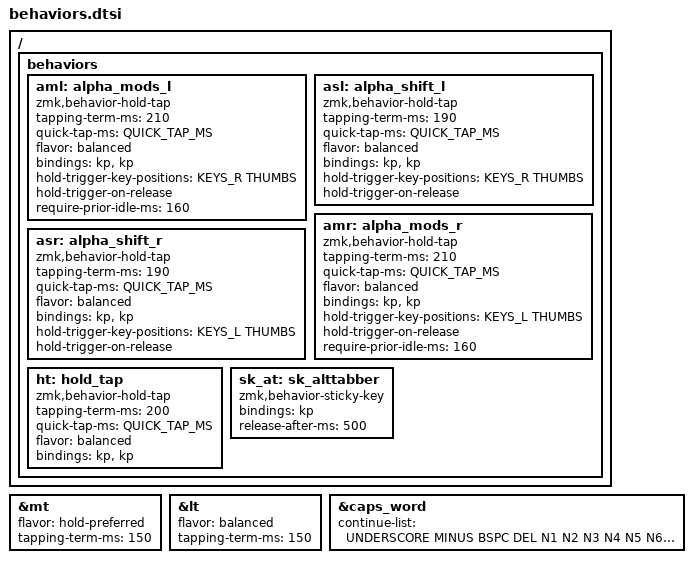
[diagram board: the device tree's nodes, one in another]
#include <behaviors.dtsi>

#define QUICK_TAP_MS 175

&mt {
    flavor = "hold-preferred";
    tapping-term-ms = <150>;
};

&lt {
    flavor = "balanced";
    tapping-term-ms = <150>;
};

&caps_word {
    continue-list = <UNDERSCORE MINUS BSPC DEL N1 N2 N3 N4 N5 N6 N7 N8 N9 N0>;
};

/ {
    behaviors {
        aml: alpha_mods_l {
            compatible = "zmk,behavior-hold-tap";
            #binding-cells = <2>;
            tapping-term-ms = <210>;
            quick-tap-ms = <QUICK_TAP_MS>;
            flavor = "balanced";
            bindings = <&kp>, <&kp>;
            hold-trigger-key-positions = <KEYS_R THUMBS>;
            hold-trigger-on-release;
            require-prior-idle-ms = <160>;
        };
        asl: alpha_shift_l {
            compatible = "zmk,behavior-hold-tap";
            #binding-cells = <2>;
            tapping-term-ms = <190>;
            quick-tap-ms = <QUICK_TAP_MS>;
            flavor = "balanced";
            bindings = <&kp>, <&kp>;
            hold-trigger-key-positions = <KEYS_R THUMBS>;
            hold-trigger-on-release;
        };
        amr: alpha_mods_r {
            compatible = "zmk,behavior-hold-tap";
            #binding-cells = <2>;
            tapping-term-ms = <210>;
            quick-tap-ms = <QUICK_TAP_MS>;
            flavor = "balanced";
            bindings = <&kp>, <&kp>;
            hold-trigger-key-positions = <KEYS_L THUMBS>;
            hold-trigger-on-release;
            require-prior-idle-ms = <160>;
        };
        asr: alpha_shift_r {
            compatible = "zmk,behavior-hold-tap";
            #binding-cells = <2>;
            tapping-term-ms = <190>;
            quick-tap-ms = <QUICK_TAP_MS>;
            flavor = "balanced";
            bindings = <&kp>, <&kp>;
            hold-trigger-key-positions = <KEYS_L THUMBS>;
            hold-trigger-on-release;
        };
        ht: hold_tap {
            compatible = "zmk,behavior-hold-tap";
            #binding-cells = <2>;
            tapping-term-ms = <200>;
            quick-tap-ms = <QUICK_TAP_MS>;
            flavor = "balanced";
            bindings = <&kp>, <&kp>;
        };
        // sticky key to be used for alt-tab macro
        sk_at: sk_alttabber {
            compatible = "zmk,behavior-sticky-key";
            #binding-cells = <1>;
            bindings = <&kp>;
            release-after-ms = <500>;
        };
    };
};
